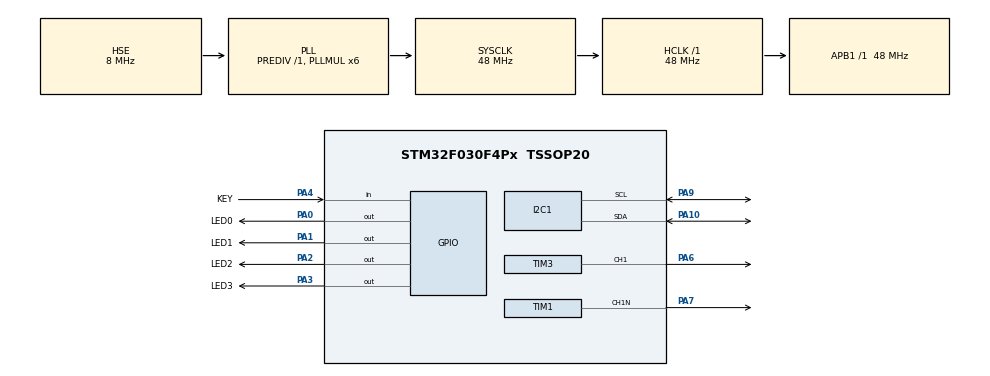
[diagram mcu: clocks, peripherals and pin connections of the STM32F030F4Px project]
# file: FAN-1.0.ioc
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Dma.Request0=TIM3_CH1/TRIG
Dma.TIM3_CH1/TRIG.0.Direction=DMA_MEMORY_TO_PERIPH
Dma.TIM3_CH1/TRIG.0.Instance=DMA1_Channel4
Dma.TIM3_CH1/TRIG.0.MemDataAlignment=DMA_MDATAALIGN_WORD
Dma.TIM3_CH1/TRIG.0.MemInc=DMA_MINC_ENABLE
Dma.TIM3_CH1/TRIG.0.Mode=DMA_NORMAL
Dma.TIM3_CH1/TRIG.0.PeriphDataAlignment=DMA_PDATAALIGN_WORD
Dma.TIM3_CH1/TRIG.0.PeriphInc=DMA_PINC_DISABLE
Dma.TIM3_CH1/TRIG.0.Priority=DMA_PRIORITY_LOW
I2C1.OwnAddress=0x0B
Mcu.Family=STM32F0
Mcu.Name=STM32F030F4Px
Mcu.Package=TSSOP20
NVIC.DMA1_Channel4_5_IRQn=true\:0\:0\:false\:false\:true\:false\:true\:true
NVIC.I2C1_IRQn=true\:0\:0\:false\:false\:true\:true\:true\:true
NVIC.TIM14_IRQn=true\:0\:0\:false\:false\:true\:true\:true\:true
PA0.GPIO_Label=LED0
PA0.GPIO_Speed=GPIO_SPEED_FREQ_HIGH
PA0.PinState=GPIO_PIN_SET
PA0.Signal=GPIO_Output
PA1.GPIO_Label=LED1
PA1.GPIO_Speed=GPIO_SPEED_FREQ_HIGH
PA1.PinState=GPIO_PIN_SET
PA1.Signal=GPIO_Output
PA10.Mode=I2C
PA10.Signal=I2C1_SDA
PA13.Mode=Serial_Wire
PA13.Signal=SYS_SWDIO
PA14.Mode=Serial_Wire
PA14.Signal=SYS_SWCLK
PA2.GPIO_Label=LED2
PA2.GPIO_Speed=GPIO_SPEED_FREQ_HIGH
PA2.PinState=GPIO_PIN_SET
PA2.Signal=GPIO_Output
PA3.GPIO_Label=LED3
PA3.GPIO_Speed=GPIO_SPEED_FREQ_LOW
PA3.PinState=GPIO_PIN_SET
PA3.Signal=GPIO_Output
PA4.GPIO_Label=KEY
PA4.Signal=GPIO_Input
PA6.Signal=S_TIM3_CH1
PA7.Mode=PWM Generation1 CH1N
PA7.Signal=TIM1_CH1N
PA9.Mode=I2C
PA9.Signal=I2C1_SCL
PF0-OSC_IN.Mode=HSE-External-Oscillator
PF0-OSC_IN.Signal=RCC_OSC_IN
PF1-OSC_OUT.Mode=HSE-External-Oscillator
PF1-OSC_OUT.Signal=RCC_OSC_OUT
ProjectManager.HeapSize=0x200
ProjectManager.StackSize=0x400
ProjectManager.TargetToolchain=MDK-ARM V5.32
RCC.AHBFreq_Value=48000000
RCC.APB1Freq_Value=48000000
RCC.APB1TimFreq_Value=48000000
RCC.HCLKFreq_Value=48000000
RCC.PLLMUL=RCC_PLL_MUL6
RCC.PLLSourceVirtual=RCC_PLLSOURCE_HSE
RCC.SYSCLKFreq_VALUE=48000000
RCC.SYSCLKSource=RCC_SYSCLKSOURCE_PLLCLK
SH.S_TIM3_CH1.0=TIM3_CH1,PWM Generation1 CH1
TIM1.AutoReloadPreload=TIM_AUTORELOAD_PRELOAD_ENABLE
TIM1.Channel-PWM\ Generation1\ CH1N=TIM_CHANNEL_1
TIM1.Period=479
TIM1.Prescaler=99
TIM14.Period=479
TIM14.Prescaler=99
TIM3.Channel-PWM\ Generation1\ CH1=TIM_CHANNEL_1
TIM3.Period=59
VP_TIM14_VS_ClockSourceINT.Mode=Enable_Timer
VP_TIM1_VS_ClockSourceINT.Mode=Internal
board=custom

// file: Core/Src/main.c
/* USER CODE BEGIN Header */
/**
  ******************************************************************************
  * @file           : main.c
  * @brief          : Main program body
  ******************************************************************************
  * @attention
  *
  * Copyright (c) 2023 STMicroelectronics.
  * All rights reserved.
  *
  * This software is licensed under terms that can be found in the LICENSE file
  * in the root directory of this software component.
  * If no LICENSE file comes with this software, it is provided AS-IS.
  *
  ******************************************************************************
  */
/* USER CODE END Header */
#include "main.h"
#include "dma.h"
#include "i2c.h"
#include "tim.h"
#include "gpio.h"

#include "key.h"
#include "led.h"
#include "ws2812.h"

void SystemClock_Config(void);

/* USER CODE BEGIN 0 */
	uint8_t RE_BUFF[10];//Define the IIC receive buffer
	uint8_t TR_BUFF[10];//Define the IIC transmit  buffer
	int pwm=75;//Define duty cycle parameters (initial duty cycle 75%)
	uint8_t Mode=Manu_mode;//Defining the mode of operation(Initial mode is manual)
	uint8_t x1,x2,x3;//Defining random parameters(RGB Randomized Light Effect Code)
	uint8_t power_on=1;//Define power-up flag bits
	int seed=0;//Define random seed values£¬supplied by timer
	int temp;//Define temperature data buffer
/* USER CODE END 0 */

int main(void)
{

  /* MCU Configuration--------------------------------------------------------*/

  /* Reset of all peripherals, Initializes the Flash interface and the Systick. */
  HAL_Init();

  /* Configure the system clock */
  SystemClock_Config();

  /* Initialize all configured peripherals */
  MX_GPIO_Init();//LED, key pin initialization
  MX_DMA_Init();
  MX_I2C1_Init();
  MX_TIM1_Init();//Fan PWM Generator Initialization
  MX_TIM3_Init();//RGB PWM Generator Initialization
  MX_TIM14_Init();//1 millisecond timer
  /* USER CODE BEGIN 2 */
	HAL_TIM_Base_Start_IT(&htim14);//Enable Timer Interrupt
	HAL_TIMEx_PWMN_Start(&htim1,TIM_CHANNEL_1);//Enable Fan pwm channel

	rgb_show(6,T_3);//Set RGB initial light effect (255,255,0)

  while (1)
  {

		HAL_I2C_Slave_Receive(&hi2c1, RE_BUFF, 2, 50);//Receive IIC commands and data (Command: RE_BUFF[0]; Data:RE_BUFF[1])

		if(RE_BUFF[0]==0x01)//Command received as 0x01: start of IIC communication
		{
			TR_BUFF[0]=RE_BUFF[1];
			HAL_I2C_Slave_Transmit(&hi2c1, TR_BUFF, 1,50);//Return to ready command: 0x00
//			time_count=IIC_OK;

			power_on=0;//Waiting for power-up handshake to end
			Mode=Auto_mode;//The IIC handshake data is received and the mode is set to auto mode.
			RE_BUFF[0]=0;
		}

		if(RE_BUFF[0]==0x02)//Command received as 0x02: Query the current operating mode
		{
			TR_BUFF[0]=Mode;
			HAL_I2C_Slave_Transmit(&hi2c1, TR_BUFF, 1,50);//Returns the current operating mode
		}

		if(RE_BUFF[0]==0x03)//Command received as 0x03:Receive temperature data
		{
			temp=RE_BUFF[1];
			if(Mode==Auto_mode)// If it is currently in auto mode, it receives the temperature data and sets the fan PWM according to the temperature
			{
				if(temp<40)
					pwm=40;
				else if(temp>=40&&temp<50)
					pwm=50;
				else if(temp>=50&&temp<55)
					pwm=75;
				else if(temp>=55&&temp<60)
					pwm=90;
				else if(temp>=60)
					pwm=100;
			}
		}

		if(power_on==1)//Handshake data not received, set mode to manual mode
		{
			Mode=Manu_mode;
		}

//		else if(power_on==0)
//		{
////			if
//			Mode=Auto_mode;
////			power_on=0;
//		}
		key_scanf();

	}
  /* USER CODE END 3 */
}

void SystemClock_Config(void)
{
  RCC_OscInitTypeDef RCC_OscInitStruct = {0};
  RCC_ClkInitTypeDef RCC_ClkInitStruct = {0};
  RCC_PeriphCLKInitTypeDef PeriphClkInit = {0};

  /** Initializes the RCC Oscillators according to the specified parameters
  * in the RCC_OscInitTypeDef structure.
  */
  RCC_OscInitStruct.OscillatorType = RCC_OSCILLATORTYPE_HSI|RCC_OSCILLATORTYPE_HSE;
  RCC_OscInitStruct.HSEState = RCC_HSE_ON;
  RCC_OscInitStruct.HSIState = RCC_HSI_ON;
  RCC_OscInitStruct.HSICalibrationValue = RCC_HSICALIBRATION_DEFAULT;
  RCC_OscInitStruct.PLL.PLLState = RCC_PLL_ON;
  RCC_OscInitStruct.PLL.PLLSource = RCC_PLLSOURCE_HSE;
  RCC_OscInitStruct.PLL.PLLMUL = RCC_PLL_MUL6;
  RCC_OscInitStruct.PLL.PREDIV = RCC_PREDIV_DIV1;
  if (HAL_RCC_OscConfig(&RCC_OscInitStruct) != HAL_OK)
  {
    Error_Handler();
  }

  /** Initializes the CPU, AHB and APB buses clocks
  */
  RCC_ClkInitStruct.ClockType = RCC_CLOCKTYPE_HCLK|RCC_CLOCKTYPE_SYSCLK
                              |RCC_CLOCKTYPE_PCLK1;
  RCC_ClkInitStruct.SYSCLKSource = RCC_SYSCLKSOURCE_PLLCLK;
  RCC_ClkInitStruct.AHBCLKDivider = RCC_SYSCLK_DIV1;
  RCC_ClkInitStruct.APB1CLKDivider = RCC_HCLK_DIV1;

  if (HAL_RCC_ClockConfig(&RCC_ClkInitStruct, FLASH_LATENCY_1) != HAL_OK)
  {
    Error_Handler();
  }
  PeriphClkInit.PeriphClockSelection = RCC_PERIPHCLK_I2C1;
  PeriphClkInit.I2c1ClockSelection = RCC_I2C1CLKSOURCE_HSI;
  if (HAL_RCCEx_PeriphCLKConfig(&PeriphClkInit) != HAL_OK)
  {
    Error_Handler();
  }
}

void Error_Handler(void)
{
  __disable_irq();
  while (1)
  {
  }
}
